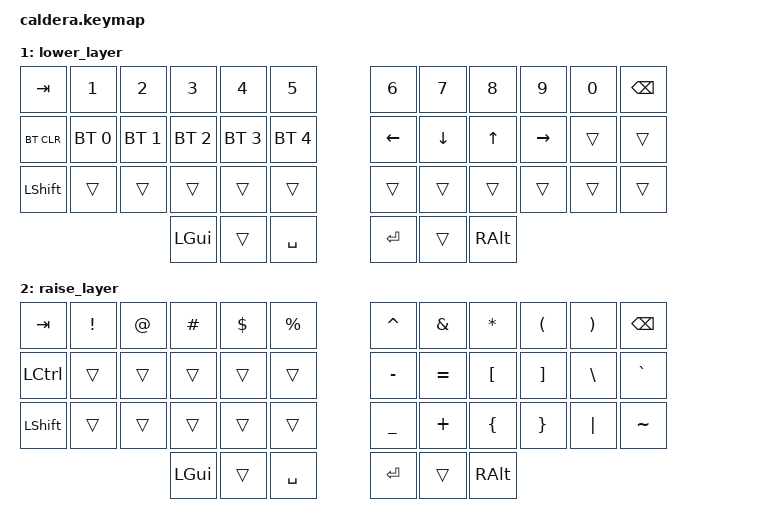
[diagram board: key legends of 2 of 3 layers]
/*
 * Copyright (c) 2020 The ZMK Contributors
 *
 * SPDX-License-Identifier: MIT
 */

#include <behaviors.dtsi>
#include <dt-bindings/zmk/keys.h>
#include <dt-bindings/zmk/bt.h>

/ {
        keymap {
                compatible = "zmk,keymap";

                default_layer {
// -----------------------------------------------------------------------------------------
// | ESC |  N1  |  N2  |  N3  |  N4  |  N5 |        |  N6 |  N7  |  N8  |  N9  |  N0  | BSPC |
// | TAB |  Q   |  W   |  E   |  R   |  T  |        | Y   | U    | I    | O    | P    | FSLH |
// | CAPS|  A   |  S   |  D   |  F   |  G  |        | H   | J    | K    | L    | SEMI | APOS |
// |LSHFT|  Z   |  X   |  C   |  V   |  B  |        | N   | M    | COMMA| DOT  | BSLH | RSHFT|
// |LCTRL| LCMD |      | LALT | ENTER|SPACE|        |SPACE| LEFT |  UP  | DOWN |RIGHT | RCTRL|

                        bindings = <
   &kp GRAVE  &kp N1    &kp N2    &kp N3     &kp N4     &kp N5               &kp N6     &kp N7  &kp N8     &kp N9    &kp N0    &kp BSPC
   &kp TAB    &kp Q     &kp W     &kp E      &kp R      &kp T                &kp Y      &kp U   &kp I      &kp O     &kp P     &kp BSLH
   &kp CAPS   &kp A     &kp S     &kp D      &kp F      &kp G                &kp H      &kp J   &kp K      &kp L     &kp SEMI  &kp RET
   &kp LSHFT  &kp Z     &kp X     &kp C      &kp V      &kp B                &kp N      &kp M   &kp COMMA  &kp DOT   &kp FSLH  &kp APOS
   &kp LCTRL  &kp LALT  &kp LGUI  &kp SPACE  &kp LALT   &kp LGUI             &kp SPACE  &mo 1   &kp LARW   &kp DARW  &kp UARW  &kp RARW
                        >;
                };
                lower_layer {
// -----------------------------------------------------------------------------------------
// | ESC | EXCL | AT | HASH | DLLR | PRCNT |   | CARET | AMPS | ASTRK | LPAR | RPAR | UNDER |
// | TAB |      |  UP  |      |      |       |   |  LBKT | RBKT |  LBRC | RBRC |      | PIPE  |
// | CAPS| LEFT | DOWN | RIGHT|      |       |   | TILDE |      |       |      |      |  DQT  |
// |LSHFT|      |      |      |      |       |   |       |      |   LT  |  GT  | QMARK| RSHIFT|
// |LCTRL| LCMD |      | LALT | ENTER| SPACE |   | SPACE |      |       |      |      |       |
                        bindings = <
   &kp TAB    &kp N1       &kp N2       &kp N3       &kp N4       &kp N5         &kp N6   &kp N7   &kp N8 &kp N9    &kp N0 &kp BSPC
   &bt BT_CLR &bt BT_SEL 0 &bt BT_SEL 1 &bt BT_SEL 2 &bt BT_SEL 3 &bt BT_SEL 4   &kp LEFT &kp DOWN &kp UP &kp RIGHT &trans &trans
   &kp LSHFT  &trans       &trans       &trans       &trans       &trans         &trans   &trans   &trans &trans    &trans &trans
                                    &kp LGUI     &trans       &kp SPACE      &kp RET  &trans   &kp RALT
                        >;
                };

                raise_layer {
// -----------------------------------------------------------------------------------------
// |  TAB |  !  |  @  |  #  |  $  |  %  |   |  ^  |  &  |  *  |  (  |  )  | BSPC |
// | CTRL |     |     |     |     |     |   |  -  |  =  |  [  |  ]  |  \  |  `   |
// | SHFT |     |     |     |     |     |   |  _  |  +  |  {  |  }  | "|" |  ~   |
//                    | GUI |     | SPC |   | ENT |     | ALT |
                        bindings = <
   &kp  TAB  &kp EXCL &kp AT &kp HASH &kp DLLR &kp PRCNT   &kp CARET &kp AMPS  &kp ASTRK &kp LPAR &kp RPAR &kp BSPC
   &kp LCTRL &trans   &trans &trans   &trans   &trans      &kp MINUS &kp EQUAL &kp LBKT  &kp RBKT &kp BSLH &kp GRAVE
   &kp LSHFT &trans   &trans &trans   &trans   &trans      &kp UNDER &kp PLUS  &kp LBRC  &kp RBRC &kp PIPE &kp TILDE
                             &kp LGUI &trans   &kp SPACE   &kp RET   &trans    &kp RALT
                        >;
                };
        };
};
